# ESP32-C2 register map
Vendor: ESPRESSIF SYSTEMS (SHANGHAI) CO., LTD.; Series: ESP32 C-Series; File version: 11
CPU: RV32IMC r0p0, little endian, no MPU, no FPU, 0 interrupt priority bits
Address unit: 32 bits
Registers are 32-bit, read-write, reset 0x0 unless marked. A register's access mark holds for its fields unless they carry their own. Offsets are from the block's base; [hi:lo] are bit positions; lines under a group give offsets from that group; {n}, {i} and the like mark numbered series.

## ASSIST_DEBUG — Debug Assist
Base 0x600CE000
{0x0+0x30*i} CPU{i} (i=0..0) group — Cluster CPU{i}, containing CORE_?_DEBUG_MODE, CORE_?_INTR_CLR, CORE_?_INTR_ENA, CORE_?_INTR_RAW, CORE_?_LASTPC_BEFORE_EXCEPTION, CORE_?_MONTR_ENA, CORE_?_RCD_EN, CORE_?_RCD_PDEBUGPC, CORE_?_RCD_PDEBUGSP, CORE_?_SP_MAX, CORE_?_SP_MIN, CORE_?_SP_PC
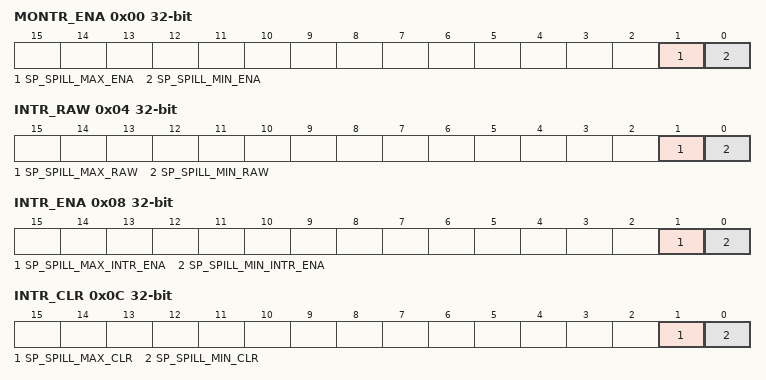
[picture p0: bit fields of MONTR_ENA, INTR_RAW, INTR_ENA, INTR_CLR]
  0x00 MONTR_ENA — core0 monitor enable configuration register
    [1] SP_SPILL_MAX_ENA — enbale sp overflow monitor
    [0] SP_SPILL_MIN_ENA — enbale sp underlow monitor
  0x04 INTR_RAW ro — core0 monitor interrupt status register
    [1] SP_SPILL_MAX_RAW — sp overflow monitor interupt status register
    [0] SP_SPILL_MIN_RAW — sp underlow monitor interrupt status register
  0x08 INTR_ENA — core0 monitor interrupt enable register
    [1] SP_SPILL_MAX_INTR_ENA — enbale sp overflow monitor interrupt
    [0] SP_SPILL_MIN_INTR_ENA — enbale sp underlow monitor interrupt
  0x0C INTR_CLR wo — core0 monitor interrupt clr register
    [1] SP_SPILL_MAX_CLR — clr sp overflow monitor interrupt
    [0] SP_SPILL_MIN_CLR — clr sp underlow monitor interrupt
  0x10 SP_MIN — stack min value
    [31:0] SP_MIN — core0 sp region configuration regsiter
  0x14 SP_MAX reset 0xFFFFFFFF — stack max value
    [31:0] SP_MAX — core0 sp pc status register
  0x18 SP_PC ro — stack monitor pc status register
    [31:0] SP_PC — This regsiter stores the PC when trigger stack monitor.
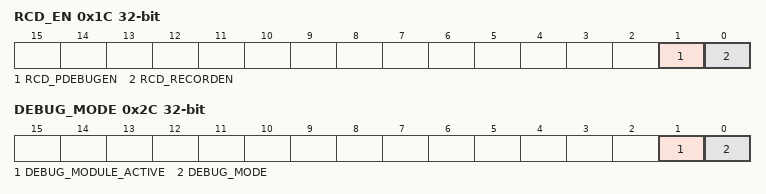
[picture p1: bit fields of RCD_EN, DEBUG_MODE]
  0x1C RCD_EN — record enable configuration register
    [1] RCD_PDEBUGEN — Set 1 to enable cpu pdebug function, must set this bit can get cpu PC
    [0] RCD_RECORDEN — Set 1 to enable record PC
  0x20 RCD_PDEBUGPC ro — record status regsiter
    [31:0] RCD_PDEBUGPC — recorded PC
  0x24 RCD_PDEBUGSP ro — record status regsiter
    [31:0] RCD_PDEBUGSP — recorded sp
  0x28 LASTPC_BEFORE_EXCEPTION ro — cpu status register
    [31:0] LASTPC_BEFORE_EXC — cpu's lastpc before exception
  0x2C DEBUG_MODE ro — cpu status register
    [1] DEBUG_MODULE_ACTIVE — cpu debug_module active status
    [0] DEBUG_MODE — cpu debug mode status, 1 means cpu enter debug mode.
0x30 CLOCK_GATE reset 0x1
  [0] CLK_EN
0x1FC DATE — version register

## BB — BB Peripheral
Base 0x6001D000
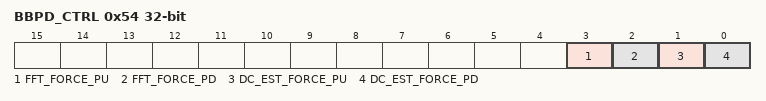
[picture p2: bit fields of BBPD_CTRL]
0x54 BBPD_CTRL — Baseband control register
  [3] FFT_FORCE_PU, [2] FFT_FORCE_PD, [1] DC_EST_FORCE_PU, [0] DC_EST_FORCE_PD

## ECC — ECC (ECC Hardware Accelerator)
Base 0x6003E000
0x0C MULT_INT_RAW ro — I2S interrupt raw register, valid in level.
  [0] CALC_DONE — The raw interrupt status bit for the i2s_tx_hung_int interrupt
0x10 MULT_INT_ST ro — I2S interrupt status register.
  [0] CALC_DONE — The masked interrupt status bit for the i2s_rx_done_int interrupt
0x14 MULT_INT_ENA — I2S interrupt enable register.
  [0] CALC_DONE — The interrupt enable bit for the i2s_rx_done_int interrupt
0x18 MULT_INT_CLR wo — I2S interrupt clear register.
  [0] CALC_DONE write-1-clears — Set this bit to clear the i2s_rx_done_int interrupt
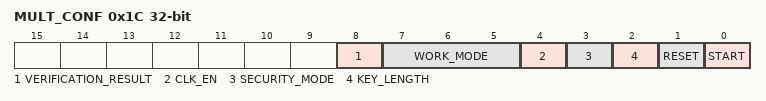
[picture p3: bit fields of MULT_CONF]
0x1C MULT_CONF access per field — I2S RX configure register
  [8] VERIFICATION_RESULT ro — Represents the verification result of ECC Accelerator, valid only when calculation is done.
  [7:5] WORK_MODE rw — Configures the work mode of ECC Accelerator.
  [4] CLK_EN rw — Configures whether to force on register clock gate.
  [3] SECURITY_MODE rw — Configures the security mode of ECC Accelerator.
  [2] KEY_LENGTH rw — Configures the key length mode bit of ECC Accelerator.
    0=P192 (P-192 elliptic curve); 1=P256 (P-256 elliptic curve)
  [1] RESET wo — Configures whether to reset ECC Accelerator.
  [0] START rw — Configures whether to start calculation of ECC Accelerator.
0xFC MULT_DATE — Version control register
{0x100+4i} K_MEM[{i}] (i=0..7) access not given — The memory that stores k.
{0x120+4i} PX_MEM[{i}] (i=0..7) access not given — The memory that stores Px.
{0x140+4i} PY_MEM[{i}] (i=0..7) access not given — The memory that stores Py.
